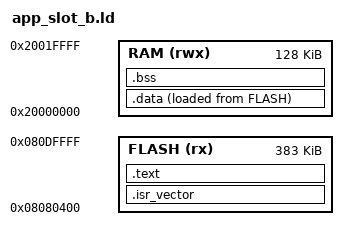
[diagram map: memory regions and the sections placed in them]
/* Application linked to run from Slot B. Image header occupies the first 0x400 bytes of the slot. */
ENTRY(Reset_Handler)

MEMORY
{
    FLASH (rx)  : ORIGIN = 0x08080400, LENGTH = 384K - 0x400
    RAM   (rwx) : ORIGIN = 0x20000000, LENGTH = 128K
}

_estack = ORIGIN(RAM) + LENGTH(RAM);

SECTIONS
{
    .isr_vector : { KEEP(*(.isr_vector)) } > FLASH
    .text : { *(.text*) *(.rodata*) . = ALIGN(4); } > FLASH
    _sidata = LOADADDR(.data);
    .data : { _sdata = .; *(.data*) . = ALIGN(4); _edata = .; } > RAM AT > FLASH
    .bss  : { _sbss = .; *(.bss*) *(COMMON) . = ALIGN(4); _ebss = .; } > RAM
    /DISCARD/ : { *(.ARM.exidx*) *(.comment) }
}
